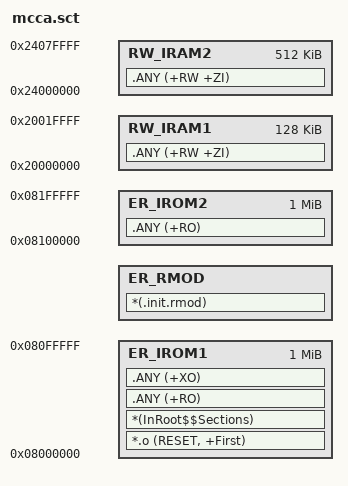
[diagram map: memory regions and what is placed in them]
; *************************************************************
; *** Scatter-Loading Description File (hand written)        ***
; *** Same map as the uVision generated file, plus ER_RMOD,  ***
; *** which collects .init.rmod so that RMOD_LIST self-       ***
; *** registration works on ARM as it does on x86.           ***
; *************************************************************

LR_IROM1 0x08000000 0x00100000  {    ; load region size_region
  ER_IROM1 0x08000000 0x00100000  {  ; load address = execution address
   *.o (RESET, +First)
   *(InRoot$$Sections)
   .ANY (+RO)
   .ANY (+XO)
  }
  ER_RMOD +0  {                      ; driver self-registration table
   *(.init.rmod)
  }
  RW_IRAM1 0x20000000 0x00020000  {  ; RW data
   .ANY (+RW +ZI)
  }
  RW_IRAM2 0x24000000 0x00080000  {
   .ANY (+RW +ZI)
  }
}

LR_IROM2 0x08100000 0x00100000  {
  ER_IROM2 0x08100000 0x00100000  {  ; load address = execution address
   .ANY (+RO)
  }
}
